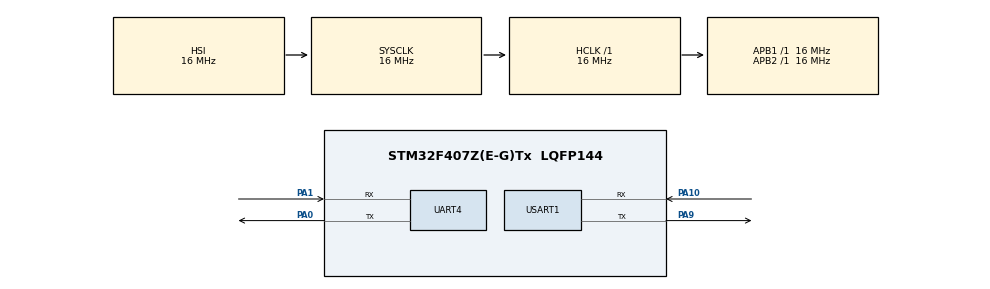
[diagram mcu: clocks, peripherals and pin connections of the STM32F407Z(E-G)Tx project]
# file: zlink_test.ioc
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Mcu.Family=STM32F4
Mcu.Name=STM32F407Z(E-G)Tx
Mcu.Package=LQFP144
NVIC.PriorityGroup=NVIC_PRIORITYGROUP_4
NVIC.UART4_IRQn=true\:0\:0\:false\:false\:true\:true\:true\:true
PA0-WKUP.Mode=Asynchronous
PA0-WKUP.Signal=UART4_TX
PA1.Mode=Asynchronous
PA1.Signal=UART4_RX
PA10.Mode=Asynchronous
PA10.Signal=USART1_RX
PA9.Mode=Asynchronous
PA9.Signal=USART1_TX
ProjectManager.HeapSize=0x200
ProjectManager.StackSize=0x400
ProjectManager.TargetToolchain=CMake
RCC.AHBFreq_Value=16000000
RCC.APB1Freq_Value=16000000
RCC.APB2Freq_Value=16000000
RCC.CortexFreq_Value=16000000
RCC.HSE_VALUE=25000000
RCC.HSI_VALUE=16000000
RCC.LSE_VALUE=32768
RCC.SYSCLKFreq_VALUE=16000000
RCC.VCOOutputFreq_Value=192000000
UART4.VirtualMode=Asynchronous
USART1.VirtualMode=VM_ASYNC
board=custom

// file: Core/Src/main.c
/* USER CODE BEGIN Header */
/**
  ******************************************************************************
  * @file           : main.c
  * @brief          : Main program body
  ******************************************************************************
  * @attention
  *
  * Copyright (c) 2026 STMicroelectronics.
  * All rights reserved.
  *
  * This software is licensed under terms that can be found in the LICENSE file
  * in the root directory of this software component.
  * If no LICENSE file comes with this software, it is provided AS-IS.
  *
  ******************************************************************************
  */
/* USER CODE END Header */
#include "main.h"
#include "usart.h"
#include "gpio.h"

/* USER CODE BEGIN Includes */
#include "stdio.h"
/* USER CODE END Includes */

/* USER CODE BEGIN PV */
char check_position[9]="#001PRAD!";
char release_torque[9]="#255PULK!";
char command[]="#005P0500T0000!";
char currrent_position[10]={};
/* USER CODE END PV */

void SystemClock_Config(void);

int main(void)
{

  /* MCU Configuration--------------------------------------------------------*/

  /* Reset of all peripherals, Initializes the Flash interface and the Systick. */
  HAL_Init();

  /* Configure the system clock */
  SystemClock_Config();

  /* Initialize all configured peripherals */
  MX_GPIO_Init();
  MX_UART4_Init();
  MX_USART1_UART_Init();
  /* USER CODE BEGIN 2 */
  HAL_UART_Transmit(&huart4,(uint8_t*)release_torque,sizeof(release_torque),2);

  /* USER CODE END 2 */

  /* Infinite loop */
  while (1)
  {
    HAL_UART_Transmit(&huart4,(uint8_t*)check_position,sizeof(check_position),2);
    HAL_UART_Receive(&huart4,(uint8_t*)currrent_position,sizeof(currrent_position),6);
    printf("%s\r\n",currrent_position);
    for(uint8_t i=5,j=5;i<=8;i++,j++)
    {
      command[i]=currrent_position[j];
    }
    if(command[5]==2 && command[6]==5)
    {continue;}
    else
    {HAL_UART_Transmit(&huart4,(uint8_t*)command,sizeof(command),2);}
    //HAL_Delay(100);
  }
}

void SystemClock_Config(void)
{
  RCC_OscInitTypeDef RCC_OscInitStruct = {0};
  RCC_ClkInitTypeDef RCC_ClkInitStruct = {0};

  /** Configure the main internal regulator output voltage
  */
  __HAL_RCC_PWR_CLK_ENABLE();
  __HAL_PWR_VOLTAGESCALING_CONFIG(PWR_REGULATOR_VOLTAGE_SCALE1);

  /** Initializes the RCC Oscillators according to the specified parameters
  * in the RCC_OscInitTypeDef structure.
  */
  RCC_OscInitStruct.OscillatorType = RCC_OSCILLATORTYPE_HSI;
  RCC_OscInitStruct.HSIState = RCC_HSI_ON;
  RCC_OscInitStruct.HSICalibrationValue = RCC_HSICALIBRATION_DEFAULT;
  RCC_OscInitStruct.PLL.PLLState = RCC_PLL_NONE;
  if (HAL_RCC_OscConfig(&RCC_OscInitStruct) != HAL_OK)
  {
    Error_Handler();
  }

  /** Initializes the CPU, AHB and APB buses clocks
  */
  RCC_ClkInitStruct.ClockType = RCC_CLOCKTYPE_HCLK|RCC_CLOCKTYPE_SYSCLK
                              |RCC_CLOCKTYPE_PCLK1|RCC_CLOCKTYPE_PCLK2;
  RCC_ClkInitStruct.SYSCLKSource = RCC_SYSCLKSOURCE_HSI;
  RCC_ClkInitStruct.AHBCLKDivider = RCC_SYSCLK_DIV1;
  RCC_ClkInitStruct.APB1CLKDivider = RCC_HCLK_DIV1;
  RCC_ClkInitStruct.APB2CLKDivider = RCC_HCLK_DIV1;

  if (HAL_RCC_ClockConfig(&RCC_ClkInitStruct, FLASH_LATENCY_0) != HAL_OK)
  {
    Error_Handler();
  }
}

/* USER CODE BEGIN 4 */
/*串口打印*/
int _write(int file,char *ptr,int len)
{
  if(HAL_UART_Transmit(&huart1,(uint8_t*)ptr,len,HAL_MAX_DELAY)!=HAL_OK)
  {return -1;}

  return len;
}
/* USER CODE END 4 */

void Error_Handler(void)
{
  __disable_irq();
  while (1)
  {
  }
}
